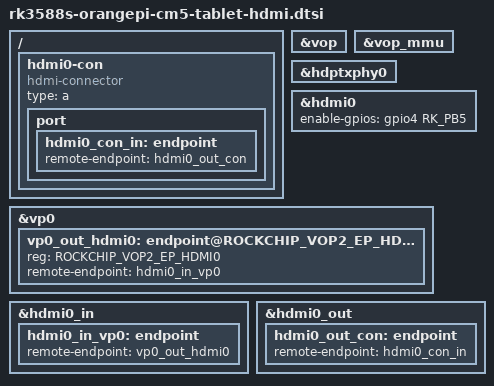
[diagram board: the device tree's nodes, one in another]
// SPDX-License-Identifier: (GPL-2.0+ OR MIT)
/* HDMI0 on the CM5 tablet carrier. GPIO4_B5 enables its HDMI output rail. */
/ {
    hdmi0-con {
        compatible = "hdmi-connector";
        type = "a";
        port {
            hdmi0_con_in: endpoint {
                remote-endpoint = <&hdmi0_out_con>;
            };
        };
    };
};

&vop { status = "okay"; };
&vop_mmu { status = "okay"; };
&hdptxphy0 { status = "okay"; };

&hdmi0 {
    enable-gpios = <&gpio4 RK_PB5 GPIO_ACTIVE_HIGH>;
    status = "okay";
};

&vp0 {
    vp0_out_hdmi0: endpoint@ROCKCHIP_VOP2_EP_HDMI0 {
        reg = <ROCKCHIP_VOP2_EP_HDMI0>;
        remote-endpoint = <&hdmi0_in_vp0>;
    };
};

&hdmi0_in {
    hdmi0_in_vp0: endpoint {
        remote-endpoint = <&vp0_out_hdmi0>;
    };
};

&hdmi0_out {
    hdmi0_out_con: endpoint {
        remote-endpoint = <&hdmi0_con_in>;
    };
};

